# VIP1_VPDMA register map
Vendor: Texas Instruments
Registers are 32-bit, access per field, reset 0x0 unless marked. A register's access mark holds for its fields unless they carry their own. Offsets are as the file gives them; [hi:lo] are bit positions; {n}, {i} and the like mark numbered series.

## VIP1_VPDMA (part 4 of 5)
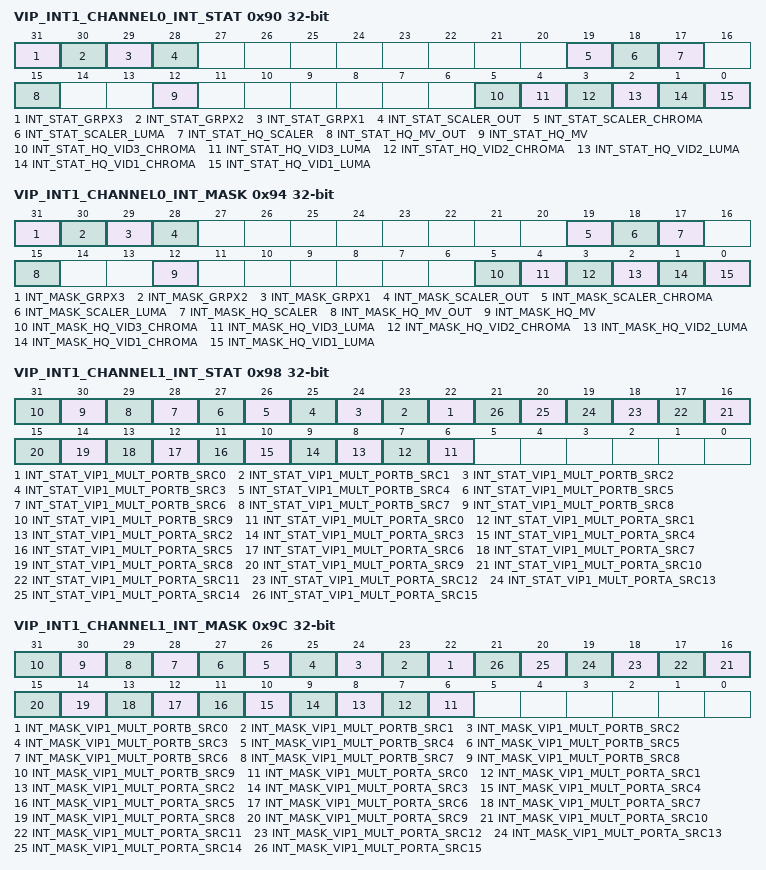
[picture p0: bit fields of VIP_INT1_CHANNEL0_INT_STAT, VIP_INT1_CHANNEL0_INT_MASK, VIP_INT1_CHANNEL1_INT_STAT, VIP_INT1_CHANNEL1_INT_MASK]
0x90 VIP_INT1_CHANNEL0_INT_STAT — This register gives the information of the interrupts that have triggered since last cleared by the process that is servicing vpdma_int1.
  [31] INT_STAT_GRPX3 rw — The last write DMA transaction has completed for channel scaler_out. All data from the channel has been sent and received by the external memory. If a new channel has not been setup for the client sc_out then the client will be fully empty at this point. This event will cause a one to be set in this register until cleared by software. Write a 1 to this field to clear the value.
  [30] INT_STAT_GRPX2 rw — The last write DMA transaction has completed for channel scaler_out. All data from the channel has been sent and received by the external memory. If a new channel has not been setup for the client sc_out then the client will be fully empty at this point. This event will cause a one to be set in this register until cleared by software. Write a 1 to this field to clear the value.
  [29] INT_STAT_GRPX1 rw — The last write DMA transaction has completed for channel scaler_out. All data from the channel has been sent and received by the external memory. If a new channel has not been setup for the client sc_out then the client will be fully empty at this point. This event will cause a one to be set in this register until cleared by software. Write a 1 to this field to clear the value.
  [28] INT_STAT_SCALER_OUT rw — The last write DMA transaction has completed for channel scaler_out. All data from the channel has been sent and received by the external memory. If a new channel has not been setup for the client sc_out then the client will be fully empty at this point. This event will cause a one to be set in this register until cleared by software. Write a 1 to this field to clear the value.
  [19] INT_STAT_SCALER_CHROMA rw — The last write DMA transaction has completed for channel scaler_luma. All data from the channel has been sent and received by the external memory. If a new channel has not been setup for the client then the client will be fully empty at this point. This event will cause a one to be set in this register until cleared by software. Write a 1 to this field to clear the value.
  [18] INT_STAT_SCALER_LUMA rw — The last write DMA transaction has completed for channel scaler_luma. All data from the channel has been sent and received by the external memory. If a new channel has not been setup for the client then the client will be fully empty at this point. This event will cause a one to be set in this register until cleared by software. Write a 1 to this field to clear the value.
  [17] INT_STAT_HQ_SCALER rw — The last write DMA transaction has completed for channel hq_scaler. All data from the channel has been sent and received by the external memory. If a new channel has not been setup for the client dei_sc_out then the client will be fully empty at this point. This event will cause a one to be set in this register until cleared by software. Write a 1 to this field to clear the value.
  [15] INT_STAT_HQ_MV_OUT rw — The last write DMA transaction has completed for channel hq_mv_out. All data from the channel has been sent and received by the external memory. If a new channel has not been setup for the client dei_hq_mv_out then the client will be fully empty at this point. This event will cause a one to be set in this register until cleared by software. Write a 1 to this field to clear the value.
  [12] INT_STAT_HQ_MV rw — The last read DMA transaction has occurred for channel hq_mv and the channel is free to be updated for the next transfer. This will fire before the destination has received the data as it will have just been stored in the internal buffer. The client dei_hq_mv_in will now accept a new descriptor from the List Manager. This event will cause a one to be set in this register until cleared by software. Write a 1 to this field to clear the value.
  [5] INT_STAT_HQ_VID3_CHROMA rw — The last write DMA transaction has completed for channel hq_vid3_chroma. All data from the channel has been sent and received by the external memory. If a new channel has not been setup for the client then the client will be fully empty at this point. This event will cause a one to be set in this register until cleared by software. Write a 1 to this field to clear the value.
  [4] INT_STAT_HQ_VID3_LUMA rw — The last write DMA transaction has completed for channel hq_vid3_luma. All data from the channel has been sent and received by the external memory. If a new channel has not been setup for the client then the client will be fully empty at this point. This event will cause a one to be set in this register until cleared by software. Write a 1 to this field to clear the value.
  [3] INT_STAT_HQ_VID2_CHROMA rw — The last write DMA transaction has completed for channel hq_vid2_chroma. All data from the channel has been sent and received by the external memory. If a new channel has not been setup for the client then the client will be fully empty at this point. This event will cause a one to be set in this register until cleared by software. Write a 1 to this field to clear the value.
  [2] INT_STAT_HQ_VID2_LUMA rw — The last write DMA transaction has completed for channel hq_vid2_luma. All data from the channel has been sent and received by the external memory. If a new channel has not been setup for the client then the client will be fully empty at this point. This event will cause a one to be set in this register until cleared by software. Write a 1 to this field to clear the value.
  [1] INT_STAT_HQ_VID1_CHROMA rw — The last write DMA transaction has completed for channel hq_vid1_chroma. All data from the channel has been sent and received by the external memory. If a new channel has not been setup for the client then the client will be fully empty at this point. This event will cause a one to be set in this register until cleared by software. Write a 1 to this field to clear the value.
  [0] INT_STAT_HQ_VID1_LUMA rw — The last write DMA transaction has completed for channel hq_vid1_luma. All data from the channel has been sent and received by the external memory. If a new channel has not been setup for the client then the client will be fully empty at this point. This event will cause a one to be set in this register until cleared by software. Write a 1 to this field to clear the value.
0x94 VIP_INT1_CHANNEL0_INT_MASK — The register gives the information of the interrupts that should be masked and not generate an interrupt for vpdma_int1.
  [31] INT_MASK_GRPX3 rw — The interrupt for Graphcis 2 Data should generate an interrupt on interrupt vpdma_int1. Write a 1 for the interrupt event to trigger the interrupt signal.
  [30] INT_MASK_GRPX2 rw — The interrupt for Graphics 1 Data should generate an interrupt on interrupt vpdma_int1. Write a 1 for the interrupt event to trigger the interrupt signal.
  [29] INT_MASK_GRPX1 rw — The interrupt for Graphics 0 Data should generate an interrupt on interrupt vpdma_int1. Write a 1 for the interrupt event to trigger the interrupt signal.
  [28] INT_MASK_SCALER_OUT rw — The interrupt for Low Cost DEI Scalar Write to Memory should generate an interrupt on interrupt vpdma_int1. Write a 1 for the interrupt event to trigger the interrupt signal.
  [19] INT_MASK_SCALER_CHROMA rw — The interrupt for should generate an interrupt on interrupt vpdma_int1. Write a 1 for the interrupt event to trigger the interrupt signal.
  [18] INT_MASK_SCALER_LUMA rw — The interrupt for should generate an interrupt on interrupt vpdma_int1. Write a 1 for the interrupt event to trigger the interrupt signal.
  [17] INT_MASK_HQ_SCALER rw — The interrupt for High Quality DEI Scaler Write to Memory should generate an interrupt on interrupt vpdma_int1. Write a 1 for the interrupt event to trigger the interrupt signal.
  [15] INT_MASK_HQ_MV_OUT rw — The interrupt for Low Cost DEI Motion Vector Write should generate an interrupt on interrupt vpdma_int1. Write a 1 for the interrupt event to trigger the interrupt signal.
  [12] INT_MASK_HQ_MV rw — The interrupt for Low Cost DEI Motion Vector should generate an interrupt on interrupt vpdma_int1. Write a 1 for the interrupt event to trigger the interrupt signal.
  [5] INT_MASK_HQ_VID3_CHROMA rw — The interrupt for should generate an interrupt on interrupt vpdma_int1. Write a 1 for the interrupt event to trigger the interrupt signal.
  [4] INT_MASK_HQ_VID3_LUMA rw — The interrupt for should generate an interrupt on interrupt vpdma_int1. Write a 1 for the interrupt event to trigger the interrupt signal.
  [3] INT_MASK_HQ_VID2_CHROMA rw — The interrupt for should generate an interrupt on interrupt vpdma_int1. Write a 1 for the interrupt event to trigger the interrupt signal.
  [2] INT_MASK_HQ_VID2_LUMA rw — The interrupt for should generate an interrupt on interrupt vpdma_int1. Write a 1 for the interrupt event to trigger the interrupt signal.
  [1] INT_MASK_HQ_VID1_CHROMA rw — The interrupt for should generate an interrupt on interrupt vpdma_int1. Write a 1 for the interrupt event to trigger the interrupt signal.
  [0] INT_MASK_HQ_VID1_LUMA rw — The interrupt for should generate an interrupt on interrupt vpdma_int1. Write a 1 for the interrupt event to trigger the interrupt signal.
0x98 VIP_INT1_CHANNEL1_INT_STAT — This register gives the information of the interrupts that have triggered since last cleared by the process that is servicing vpdma_int1.
  [n+22] INT_STAT_VIP1_MULT_PORTB_SRC{n} rw (n=0..9) — The last write DMA transaction has completed for channel vip1_mult_portb_src{n}. All data from the channel has been sent and received by the external memory. If a new channel has not been setup for the client vip1_lo_uv then the client will be fully empty at this point. This event will cause a one to be set in this register until cleared by software. Write a 1 to this field to clear the value.
  [n+6] INT_STAT_VIP1_MULT_PORTA_SRC{n} rw (n=0..15) — The last write DMA transaction has completed for channel vip1_mult_porta_src{n}. All data from the channel has been sent and received by the external memory. If a new channel has not been setup for the client vip1_lo_y then the client will be fully empty at this point. This event will cause a one to be set in this register until cleared by software. Write a 1 to this field to clear the value.
0x9C VIP_INT1_CHANNEL1_INT_MASK — The register gives the information of the interrupts that should be masked and not generate an interrupt for vpdma_int1.
  [n+22] INT_MASK_VIP1_MULT_PORTB_SRC{n} rw (n=0..9) — The interrupt for Video Input 1 Port B Channel {n} should generate an interrupt on interrupt vpdma_int1. Write a 1 for the interrupt event to trigger the interrupt signal.
  [n+6] INT_MASK_VIP1_MULT_PORTA_SRC{n} rw (n=0..15) — The interrupt for Video Input 1 Port A Channel {n} should generate an interrupt on interrupt vpdma_int1. Write a 1 for the interrupt event to trigger the interrupt signal.
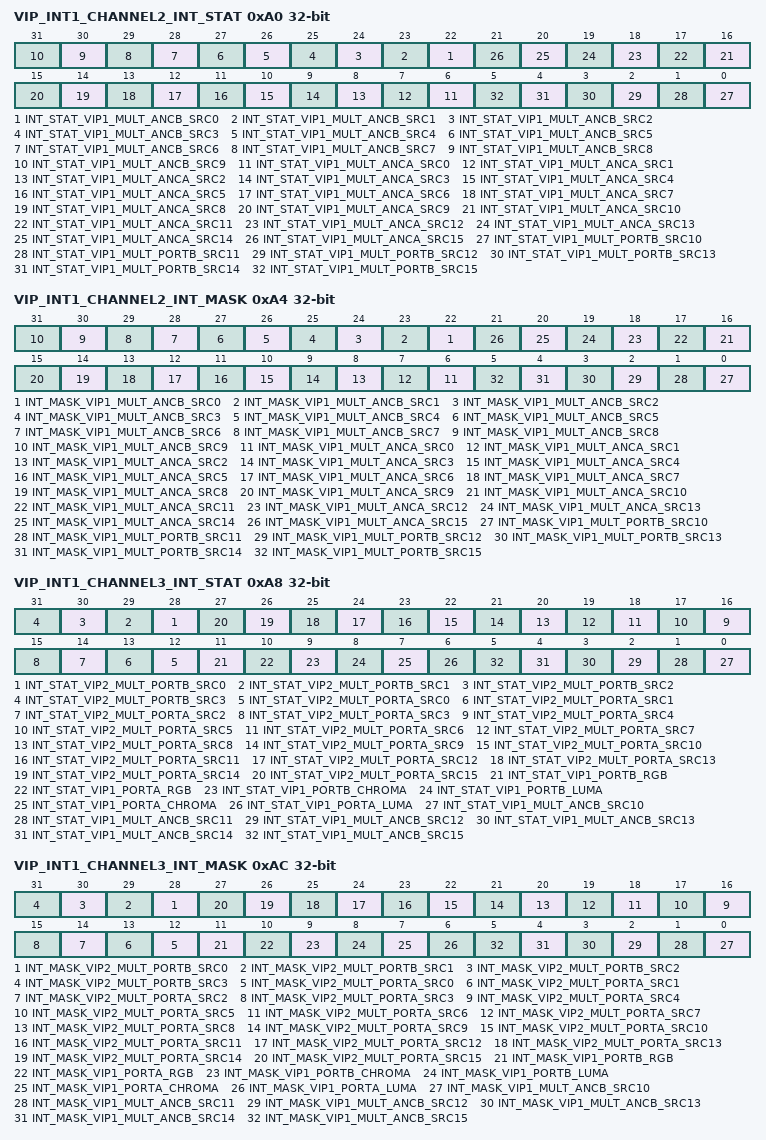
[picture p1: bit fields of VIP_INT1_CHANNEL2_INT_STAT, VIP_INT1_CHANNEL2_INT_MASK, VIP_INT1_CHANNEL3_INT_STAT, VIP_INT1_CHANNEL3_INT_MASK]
0xA0 VIP_INT1_CHANNEL2_INT_STAT rw — This register gives the information of the interrupts that have triggered since last cleared by the process that is servicing vpdma_int1.
  [n+22] INT_STAT_VIP1_MULT_ANCB_SRC{n} (n=0..9) — The last write DMA transaction has completed for channel vip1_mult_ancb_src{n}. All data from the channel has been sent and received by the external memory. If a new channel has not been setup for the client vip1_anc_b then the client will be fully empty at this point. This event will cause a one to be set in this register until cleared by software. Write a 1 to this field to clear the value.
  [n+6] INT_STAT_VIP1_MULT_ANCA_SRC{n} (n=0..15) — The last write DMA transaction has completed for channel vip1_mult_anca_src{n}. All data from the channel has been sent and received by the external memory. If a new channel has not been setup for the client vip1_anc_a then the client will be fully empty at this point. This event will cause a one to be set in this register until cleared by software. Write a 1 to this field to clear the value.
  [n-10] INT_STAT_VIP1_MULT_PORTB_SRC{n} (n=10..15) — The last write DMA transaction has completed for channel vip1_mult_portb_src{n}. All data from the channel has been sent and received by the external memory. If a new channel has not been setup for the client vip1_lo_uv then the client will be fully empty at this point. This event will cause a one to be set in this register until cleared by software. Write a 1 to this field to clear the value.
0xA4 VIP_INT1_CHANNEL2_INT_MASK rw — The register gives the information of the interrupts that should be masked and not generate an interrupt for vpdma_int1.
  [n+22] INT_MASK_VIP1_MULT_ANCB_SRC{n} (n=0..9) — The interrupt for Video Input 1 Port B Ancillary Data Channel {n} should generate an interrupt on interrupt vpdma_int1. Write a 1 for the interrupt event to trigger the interrupt signal.
  [n+6] INT_MASK_VIP1_MULT_ANCA_SRC{n} (n=0..15) — The interrupt for Video Input 1 Port A Ancillary Data Channel {n} should generate an interrupt on interrupt vpdma_int1. Write a 1 for the interrupt event to trigger the interrupt signal.
  [n-10] INT_MASK_VIP1_MULT_PORTB_SRC{n} (n=10..15) — The interrupt for Video Input 1 Port B Channel {n} should generate an interrupt on interrupt vpdma_int1. Write a 1 for the interrupt event to trigger the interrupt signal.
0xA8 VIP_INT1_CHANNEL3_INT_STAT rw — This register gives the information of the interrupts that have triggered since last cleared by the process that is servicing vpdma_int1.
  [n+28] INT_STAT_VIP2_MULT_PORTB_SRC{n} (n=0..3) — The last write DMA transaction has completed for channel vip2_mult_portb_src{n}. All data from the channel has been sent and received by the external memory. If a new channel has not been setup for the client vip2_lo_uv then the client will be fully empty at this point. This event will cause a one to be set in this register until cleared by software. Write a 1 to this field to clear the value.
  [n+12] INT_STAT_VIP2_MULT_PORTA_SRC{n} (n=0..15) — The last write DMA transaction has completed for channel vip2_mult_porta_src{n}. All data from the channel has been sent and received by the external memory. If a new channel has not been setup for the client vip2_lo_y then the client will be fully empty at this point. This event will cause a one to be set in this register until cleared by software. Write a 1 to this field to clear the value.
  [11] INT_STAT_VIP1_PORTB_RGB — The last write DMA transaction has completed for channel vip1_portb_rgb. All data from the channel has been sent and received by the external memory. If a new channel has not been setup for the client vip1_lo_y then the client will be fully empty at this point. This event will cause a one to be set in this register until cleared by software. Write a 1 to this field to clear the value.
  [10] INT_STAT_VIP1_PORTA_RGB — The last write DMA transaction has completed for channel vip1_porta_rgb. All data from the channel has been sent and received by the external memory. If a new channel has not been setup for the client vip1_up_y then the client will be fully empty at this point. This event will cause a one to be set in this register until cleared by software. Write a 1 to this field to clear the value.
  [9] INT_STAT_VIP1_PORTB_CHROMA — The last write DMA transaction has completed for channel vip1_portb_chroma. All data from the channel has been sent and received by the external memory. If a new channel has not been setup for the client then the client will be fully empty at this point. This event will cause a one to be set in this register until cleared by software. Write a 1 to this field to clear the value.
  [8] INT_STAT_VIP1_PORTB_LUMA — The last write DMA transaction has completed for channel vip1_portb_luma. All data from the channel has been sent and received by the external memory. If a new channel has not been setup for the client then the client will be fully empty at this point. This event will cause a one to be set in this register until cleared by software. Write a 1 to this field to clear the value.
  [7] INT_STAT_VIP1_PORTA_CHROMA — The last write DMA transaction has completed for channel vip1_porta_chroma. All data from the channel has been sent and received by the external memory. If a new channel has not been setup for the client then the client will be fully empty at this point. This event will cause a one to be set in this register until cleared by software. Write a 1 to this field to clear the value.
  [6] INT_STAT_VIP1_PORTA_LUMA — The last write DMA transaction has completed for channel vip1_porta_luma. All data from the channel has been sent and received by the external memory. If a new channel has not been setup for the client then the client will be fully empty at this point. This event will cause a one to be set in this register until cleared by software. Write a 1 to this field to clear the value.
  [n-10] INT_STAT_VIP1_MULT_ANCB_SRC{n} (n=10..15) — The last write DMA transaction has completed for channel vip1_mult_ancb_src{n}. All data from the channel has been sent and received by the external memory. If a new channel has not been setup for the client vip1_anc_b then the client will be fully empty at this point. This event will cause a one to be set in this register until cleared by software. Write a 1 to this field to clear the value.
0xAC VIP_INT1_CHANNEL3_INT_MASK rw — The register gives the information of the interrupts that should be masked and not generate an interrupt for vpdma_int1.
  [n+28] INT_MASK_VIP2_MULT_PORTB_SRC{n} (n=0..3) — The interrupt for Video Input 2 Port B Channel {n} should generate an interrupt on interrupt vpdma_int1. Write a 1 for the interrupt event to trigger the interrupt signal.
  [n+12] INT_MASK_VIP2_MULT_PORTA_SRC{n} (n=0..15) — The interrupt for Video Input 2 Port A Channel {n} should generate an interrupt on interrupt vpdma_int1. Write a 1 for the interrupt event to trigger the interrupt signal.
  [11] INT_MASK_VIP1_PORTB_RGB — The interrupt for Video Input 1 Port B RGB Data should generate an interrupt on interrupt vpdma_int1. Write a 1 for the interrupt event to trigger the interrupt signal.
  [10] INT_MASK_VIP1_PORTA_RGB — The interrupt for Video Input 1 Port A RGB Data should generate an interrupt on interrupt vpdma_int1. Write a 1 for the interrupt event to trigger the interrupt signal.
  [9] INT_MASK_VIP1_PORTB_CHROMA — The interrupt for should generate an interrupt on interrupt vpdma_int1. Write a 1 for the interrupt event to trigger the interrupt signal.
  [8] INT_MASK_VIP1_PORTB_LUMA — The interrupt for should generate an interrupt on interrupt vpdma_int1. Write a 1 for the interrupt event to trigger the interrupt signal.
  [7] INT_MASK_VIP1_PORTA_CHROMA — The interrupt for should generate an interrupt on interrupt vpdma_int1. Write a 1 for the interrupt event to trigger the interrupt signal.
  [6] INT_MASK_VIP1_PORTA_LUMA — The interrupt for should generate an interrupt on interrupt vpdma_int1. Write a 1 for the interrupt event to trigger the interrupt signal.
  [n-10] INT_MASK_VIP1_MULT_ANCB_SRC{n} (n=10..15) — The interrupt for Video Input 1 Port B Ancillary Data Channel {n} should generate an interrupt on interrupt vpdma_int1. Write a 1 for the interrupt event to trigger the interrupt signal.
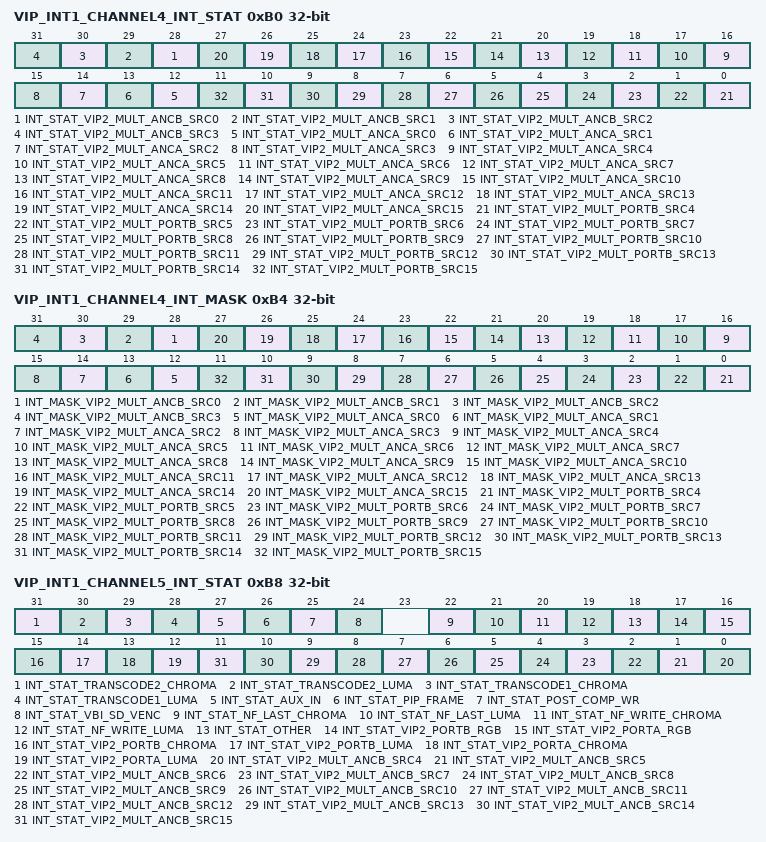
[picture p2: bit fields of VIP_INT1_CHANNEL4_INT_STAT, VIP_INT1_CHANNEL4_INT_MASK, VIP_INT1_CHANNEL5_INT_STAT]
0xB0 VIP_INT1_CHANNEL4_INT_STAT rw — This register gives the information of the interrupts that have triggered since last cleared by the process that is servicing vpdma_int1.
  [n+28] INT_STAT_VIP2_MULT_ANCB_SRC{n} (n=0..3) — The last write DMA transaction has completed for channel vip2_mult_ancb_src{n}. All data from the channel has been sent and received by the external memory. If a new channel has not been setup for the client vip2_anc_b then the client will be fully empty at this point. This event will cause a one to be set in this register until cleared by software. Write a 1 to this field to clear the value.
  [n+12] INT_STAT_VIP2_MULT_ANCA_SRC{n} (n=0..15) — The last write DMA transaction has completed for channel vip2_mult_anca_src{n}. All data from the channel has been sent and received by the external memory. If a new channel has not been setup for the client vip2_anc_a then the client will be fully empty at this point. This event will cause a one to be set in this register until cleared by software. Write a 1 to this field to clear the value.
  [n-4] INT_STAT_VIP2_MULT_PORTB_SRC{n} (n=4..15) — The last write DMA transaction has completed for channel vip2_mult_portb_src{n}. All data from the channel has been sent and received by the external memory. If a new channel has not been setup for the client vip2_lo_uv then the client will be fully empty at this point. This event will cause a one to be set in this register until cleared by software. Write a 1 to this field to clear the value.
0xB4 VIP_INT1_CHANNEL4_INT_MASK rw — The register gives the information of the interrupts that should be masked and not generate an interrupt for vpdma_int1.
  [n+28] INT_MASK_VIP2_MULT_ANCB_SRC{n} (n=0..3) — The interrupt for Video Input 2 Port B Ancillary Data Channel {n} should generate an interrupt on interrupt vpdma_int1. Write a 1 for the interrupt event to trigger the interrupt signal.
  [n+12] INT_MASK_VIP2_MULT_ANCA_SRC{n} (n=0..15) — The interrupt for Video Input 2 Port A Ancillary Data Channel {n} should generate an interrupt on interrupt vpdma_int1. Write a 1 for the interrupt event to trigger the interrupt signal.
  [n-4] INT_MASK_VIP2_MULT_PORTB_SRC{n} (n=4..15) — The interrupt for Video Input 2 Port B Channel {n} should generate an interrupt on interrupt vpdma_int1. Write a 1 for the interrupt event to trigger the interrupt signal.
0xB8 VIP_INT1_CHANNEL5_INT_STAT — This register gives the information of the interrupts that have triggered since last cleared by the process that is servicing vpdma_int1.
  [31] INT_STAT_TRANSCODE2_CHROMA rw — The last write DMA transaction has completed for channel transcode2_chroma. All data from the channel has been sent and received by the external memory. If a new channel has not been setup for the client then the client will be fully empty at this point. This event will cause a one to be set in this register until cleared by software. Write a 1 to this field to clear the value.
  [30] INT_STAT_TRANSCODE2_LUMA rw — The last write DMA transaction has completed for channel transcode2_luma. All data from the channel has been sent and received by the external memory. If a new channel has not been setup for the client then the client will be fully empty at this point. This event will cause a one to be set in this register until cleared by software. Write a 1 to this field to clear the value.
  [29] INT_STAT_TRANSCODE1_CHROMA rw — The last write DMA transaction has completed for channel transcode1_chroma. All data from the channel has been sent and received by the external memory. If a new channel has not been setup for the client then the client will be fully empty at this point. This event will cause a one to be set in this register until cleared by software. Write a 1 to this field to clear the value.
  [28] INT_STAT_TRANSCODE1_LUMA rw — The last write DMA transaction has completed for channel transcode1_luma. All data from the channel has been sent and received by the external memory. If a new channel has not been setup for the client then the client will be fully empty at this point. This event will cause a one to be set in this register until cleared by software. Write a 1 to this field to clear the value.
  [27] INT_STAT_AUX_IN rw — The last read DMA transaction has occurred for channel aux_in and the channel is free to be updated for the next transfer. This will fire before the destination has received the data as it will have just been stored in the internal buffer. The client comp_wrbk will now accept a new descriptor from the List Manager. This event will cause a one to be set in this register until cleared by software. Write a 1 to this field to clear the value.
  [26] INT_STAT_PIP_FRAME rw — The last read DMA transaction has occurred for channel pip_frame and the channel is free to be updated for the next transfer. This will fire before the destination has received the data as it will have just been stored in the internal buffer. The client pip_wrbk will now accept a new descriptor from the List Manager. This event will cause a one to be set in this register until cleared by software. Write a 1 to this field to clear the value.
  [25] INT_STAT_POST_COMP_WR rw — The last write DMA transaction has completed for channel post_comp_wr. All data from the channel has been sent and received by the external memory. If a new channel has not been setup for the client hdmi_wrbk_out then the client will be fully empty at this point. This event will cause a one to be set in this register until cleared by software. Write a 1 to this field to clear the value.
  [24] INT_STAT_VBI_SD_VENC rw — The last read DMA transaction has occurred for channel vbi_sd_venc and the channel is free to be updated for the next transfer. This will fire before the destination has received the data as it will have just been stored in the internal buffer. The client vbi_sdvenc will now accept a new descriptor from the List Manager. This event will cause a one to be set in this register until cleared by software. Write a 1 to this field to clear the value.
  [22] INT_STAT_NF_LAST_CHROMA rw — The last write DMA transaction has completed for channel nf_last_chroma. All data from the channel has been sent and received by the external memory. If a new channel has not been setup for the client then the client will be fully empty at this point. This event will cause a one to be set in this register until cleared by software. Write a 1 to this field to clear the value.
  [21] INT_STAT_NF_LAST_LUMA rw — The last write DMA transaction has completed for channel nf_last_luma. All data from the channel has been sent and received by the external memory. If a new channel has not been setup for the client then the client will be fully empty at this point. This event will cause a one to be set in this register until cleared by software. Write a 1 to this field to clear the value.
  [20] INT_STAT_NF_WRITE_CHROMA rw — The last write DMA transaction has completed for channel nf_write_chroma. All data from the channel has been sent and received by the external memory. If a new channel has not been setup for the client then the client will be fully empty at this point. This event will cause a one to be set in this register until cleared by software. Write a 1 to this field to clear the value.
  [19] INT_STAT_NF_WRITE_LUMA rw — The last write DMA transaction has completed for channel nf_write_luma. All data from the channel has been sent and received by the external memory. If a new channel has not been setup for the client then the client will be fully empty at this point. This event will cause a one to be set in this register until cleared by software. Write a 1 to this field to clear the value.
  [18] INT_STAT_OTHER rw — This event will cause a one to be set in this register until cleared by software. Write a 1 to this field to clear the value.
  [17] INT_STAT_VIP2_PORTB_RGB rw — The last write DMA transaction has completed for channel vip2_portb_rgb. All data from the channel has been sent and received by the external memory. If a new channel has not been setup for the client vip2_lo_y then the client will be fully empty at this point. This event will cause a one to be set in this register until cleared by software. Write a 1 to this field to clear the value.
  [16] INT_STAT_VIP2_PORTA_RGB rw — The last write DMA transaction has completed for channel vip2_porta_rgb. All data from the channel has been sent and received by the external memory. If a new channel has not been setup for the client vip2_up_y then the client will be fully empty at this point. This event will cause a one to be set in this register until cleared by software. Write a 1 to this field to clear the value.
  [15] INT_STAT_VIP2_PORTB_CHROMA rw — The last write DMA transaction has completed for channel vip2_portb_chroma. All data from the channel has been sent and received by the external memory. If a new channel has not been setup for the client then the client will be fully empty at this point. This event will cause a one to be set in this register until cleared by software. Write a 1 to this field to clear the value.
  [14] INT_STAT_VIP2_PORTB_LUMA rw — The last write DMA transaction has completed for channel vip2_portb_luma. All data from the channel has been sent and received by the external memory. If a new channel has not been setup for the client then the client will be fully empty at this point. This event will cause a one to be set in this register until cleared by software. Write a 1 to this field to clear the value.
  [13] INT_STAT_VIP2_PORTA_CHROMA rw — The last write DMA transaction has completed for channel vip2_porta_chroma. All data from the channel has been sent and received by the external memory. If a new channel has not been setup for the client then the client will be fully empty at this point. This event will cause a one to be set in this register until cleared by software. Write a 1 to this field to clear the value.
  [12] INT_STAT_VIP2_PORTA_LUMA rw — The last write DMA transaction has completed for channel vip2_porta_luma. All data from the channel has been sent and received by the external memory. If a new channel has not been setup for the client then the client will be fully empty at this point. This event will cause a one to be set in this register until cleared by software. Write a 1 to this field to clear the value.
  [n-4] INT_STAT_VIP2_MULT_ANCB_SRC{n} rw (n=4..15) — The last write DMA transaction has completed for channel vip2_mult_ancb_src{n}. All data from the channel has been sent and received by the external memory. If a new channel has not been setup for the client vip2_anc_b then the client will be fully empty at this point. This event will cause a one to be set in this register until cleared by software. Write a 1 to this field to clear the value.
